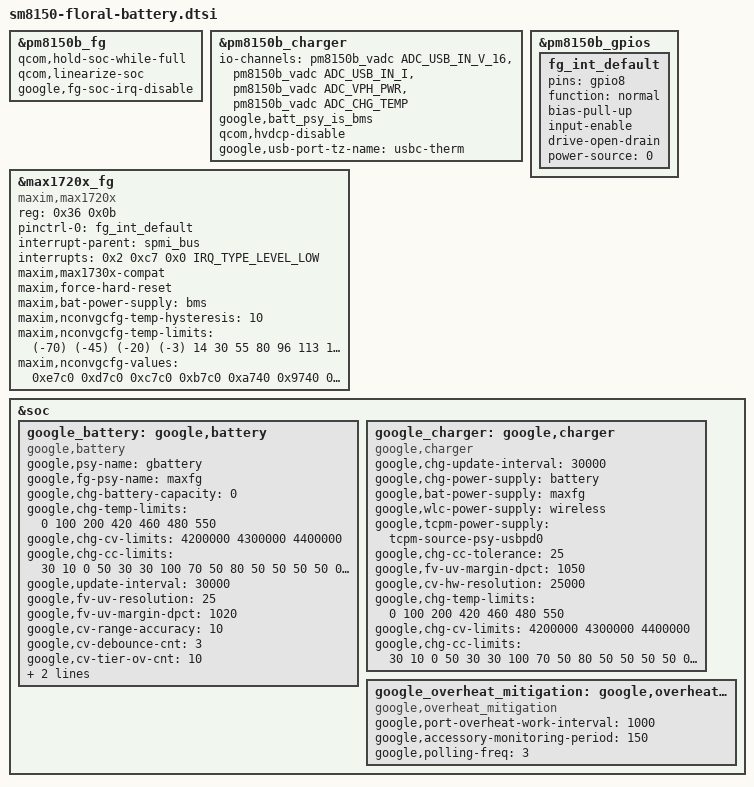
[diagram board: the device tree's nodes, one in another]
/* Copyright (c) 2018, The Linux Foundation. All rights reserved.
 *
 * This program is free software; you can redistribute it and/or modify
 * it under the terms of the GNU General Public License version 2 and
 * only version 2 as published by the Free Software Foundation.
 *
 * This program is distributed in the hope that it will be useful,
 * but WITHOUT ANY WARRANTY; without even the implied warranty of
 * MERCHANTABILITY or FITNESS FOR A PARTICULAR PURPOSE.  See the
 * GNU General Public License for more details.
 */

&pm8150b_fg {
	qcom,hold-soc-while-full;
	qcom,linearize-soc;
	google,fg-soc-irq-disable;
};

&pm8150b_charger {

	io-channels = <&pm8150b_vadc ADC_USB_IN_V_16>,
		      <&pm8150b_vadc ADC_USB_IN_I>,
		      <&pm8150b_vadc ADC_VPH_PWR>,
		      <&pm8150b_vadc ADC_CHG_TEMP>;
	io-channel-names = "usb_in_voltage",
			   "usb_in_current",
			   "vph_voltage",
			   "chg_temp";

	google,batt_psy_is_bms;
	qcom,hvdcp-disable;
	google,usb-port-tz-name = "usbc-therm";
};

&pm8150b_gpios {
	fg_int_default: fg_int_default {
		pins = "gpio8";
		function = "normal";
		bias-pull-up;
		input-enable;
		drive-open-drain;
		power-source = <0>;
	};
};

&max1720x_fg {
	compatible = "maxim,max1720x";
	reg-names = "m5db", "nvram";
	reg = <0x36 0x0b>;

	pinctrl-names = "default";
	pinctrl-0 = <&fg_int_default>;

	interrupt-parent = <&spmi_bus>;
	interrupt-names = "max1720x_fg";
	interrupts = <0x2 0xc7 0x0 IRQ_TYPE_LEVEL_LOW>;

	/* enable experimental max17301 support */
	maxim,max1730x-compat;

	maxim,force-hard-reset;
	/* FIXME: route to google_battery when available */
	maxim,bat-power-supply = "bms";

	maxim,nconvgcfg-temp-hysteresis = <10>;
	maxim,nconvgcfg-temp-limits = /bits/ 16
		<(-70) (-45) (-20) (-3) 14 30 55 80
		96 113 130 155 180 230>;
	maxim,nconvgcfg-values = /bits/ 16
		<0xe7c0 0xd7c0 0xc7c0 0xb7c0 0xa740 0x9740 0x86c0 0x7640
		0x65c0 0x54c0 0x4440 0x3340 0x2240 0x1140>;


};

&soc {
	google_battery: google,battery {
		compatible = "google,battery";

		google,psy-name = "gbattery";
		google,fg-psy-name = "maxfg";

		/* chg-battery-capacity = <0> -> read FULL_DESIGN from FG */
		google,chg-battery-capacity = <0>;
		/* charge table for floral */
		google,chg-temp-limits = <0 100 200 420 460 480 550>;
		google,chg-cv-limits = <4200000 4300000 4400000>;
		google,chg-cc-limits = <
			 30  10   0
			 50  30  30
			100  70  50
			 80  50  50
			 50  50   0
			 30   0   0
		>;

		/* battery poll rate */
		google,update-interval = <30000>;
		/* IRDrop Compensation */
		google,fv-uv-resolution = <25>;
		google,fv-uv-margin-dpct = <1020>;
		google,cv-range-accuracy = <10>;
		/* tier switch */
		google,cv-debounce-cnt = <3>;
		google,cv-tier-ov-cnt = <10>;
		google,cv-tier-switch-cnt = <3>;
		/* experimental */
		google,cv-otv-margin = <0>;
	};


	google_charger: google,charger {
		compatible = "google,charger";

		google,chg-update-interval = <30000>;

		google,chg-power-supply = "battery";
		google,bat-power-supply = "maxfg";
		google,wlc-power-supply = "wireless";
		google,tcpm-power-supply = "tcpm-source-psy-usbpd0";

		google,chg-cc-tolerance = <25>;
		google,fv-uv-margin-dpct = <1050>;

		/* FIXME: b/113611881 */
		google,cv-hw-resolution = <25000>;

		/* FIXME: charge table for floral */
		google,chg-temp-limits = <0 100 200 420 460 480 550>;
		google,chg-cv-limits = <4200000 4300000 4400000>;
		google,chg-cc-limits = <
			 30  10   0
			 50  30  30
			100  70  50
			 80  50  50
			 50  50   0
			 30   0   0
		>;
	};

	google_overheat_mitigation: google,overheat_mitigation {
		compatible = "google,overheat_mitigation";
		google,port-overheat-work-interval = <1000>;
		google,accessory-monitoring-period = <150>;
		/* Must maintain < 1/15 duty cycle */
		google,polling-freq = <3>;
	};
};


/* FIXME: bcl sensor */
